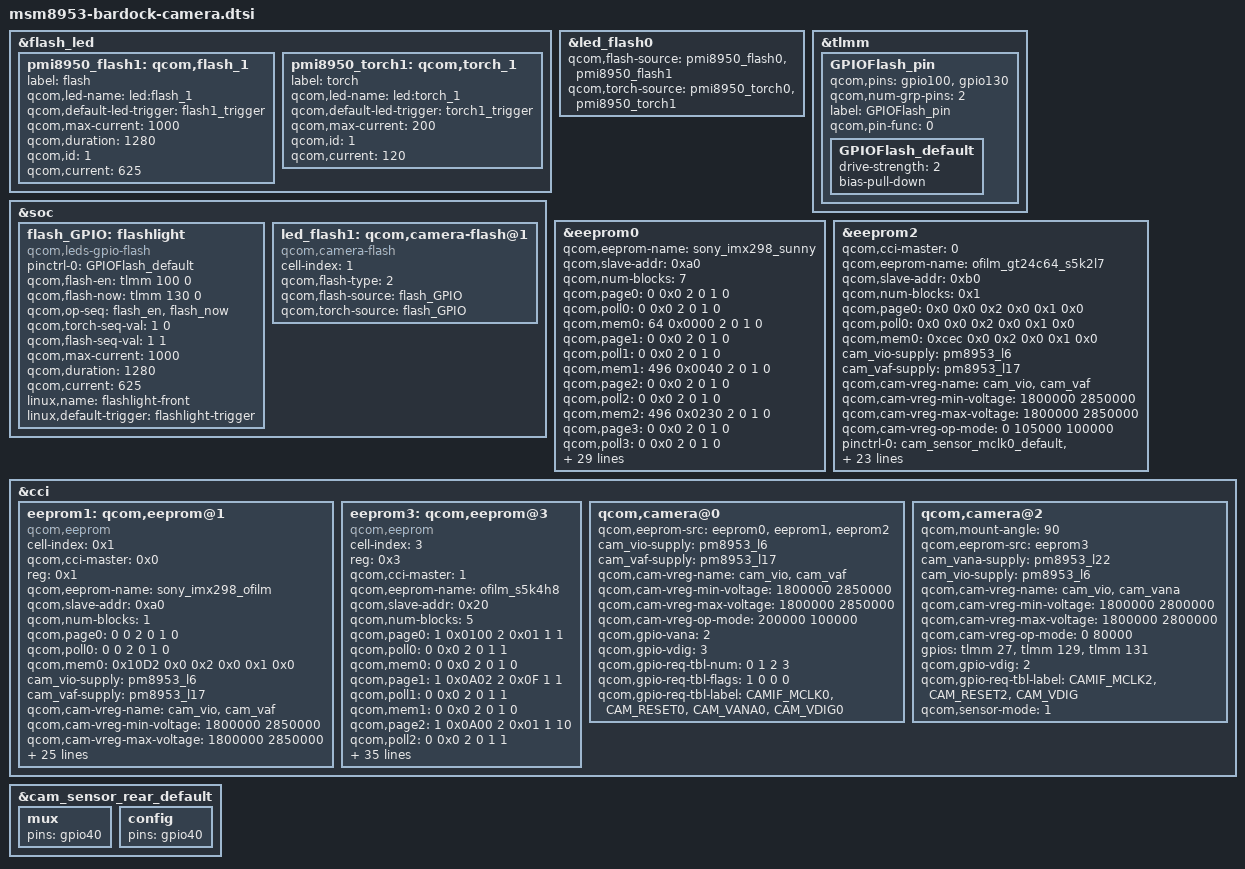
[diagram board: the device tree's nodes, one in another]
/*
 * Copyright (c) 2018, The LineageOS Project. All rights reserved.
 *
 * This program is free software; you can redistribute it and/or modify
 * it under the terms of the GNU General Public License version 2 and
 * only version 2 as published by the Free Software Foundation.
 *
 * This program is distributed in the hope that it will be useful,
 * but WITHOUT ANY WARRANTY; without even the implied warranty of
 * MERCHANTABILITY or FITNESS FOR A PARTICULAR PURPOSE.  See the
 * GNU General Public License for more details.
 */

&flash_led {
	pmi8950_flash1: qcom,flash_1 {
		label = "flash";
		qcom,led-name = "led:flash_1";
		qcom,default-led-trigger = "flash1_trigger";
		qcom,max-current = <1000>;
		qcom,duration = <1280>;
		qcom,id = <1>;
		qcom,current = <625>;
	};

	pmi8950_torch1: qcom,torch_1 {
		label = "torch";
		qcom,led-name = "led:torch_1";
		qcom,default-led-trigger = "torch1_trigger";
		qcom,max-current = <200>;
		qcom,id = <1>;
		qcom,current = <120>;
	};
};

&led_flash0 {
	qcom,flash-source = <&pmi8950_flash0 &pmi8950_flash1>;
	qcom,torch-source = <&pmi8950_torch0 &pmi8950_torch1>;
};

&tlmm {
	GPIOFlash_pin {
		qcom,pins = "gpio100", "gpio130";
		qcom,num-grp-pins = <2>;
		label = "GPIOFlash_pin";
		qcom,pin-func = <0>;

		GPIOFlash_default: GPIOFlash_default {
		drive-strength = <2>;
		bias-pull-down;
		};
	};
};

&soc {
	flash_GPIO:flashlight {
		compatible = "qcom,leds-gpio-flash";
		//status = "okay";
		pinctrl-names = "flash_default";
		pinctrl-0 = <&GPIOFlash_default>;
		qcom,flash-en = <&tlmm 100 0>;
		qcom,flash-now = <&tlmm 130 0>;
		qcom,op-seq = "flash_en", "flash_now";
		qcom,torch-seq-val = <1 0>;
		qcom,flash-seq-val = <1 1>;
                qcom,max-current = <1000>;
                qcom,duration = <1280>;
                qcom,current = <625>;
		linux,name = "flashlight-front";
		linux,default-trigger = "flashlight-trigger";
	};
	led_flash1: qcom,camera-flash@1{
		cell-index = <1>;
		compatible = "qcom,camera-flash";
		qcom,flash-type = <2>;
		qcom,flash-source = <&flash_GPIO>;
		qcom,torch-source = <&flash_GPIO>;
	};
};

	&eeprom0 {
		qcom,eeprom-name = "sony_imx298_sunny";
		qcom,slave-addr = <0xa0>;
		qcom,num-blocks = <7>;
		qcom,page0 = <0 0x0 2 0 1 0>;
		qcom,poll0 = <0 0x0 2 0 1 0>;
		qcom,mem0 = <64 0x0000 2 0 1 0>;
		qcom,page1 = <0 0x0 2 0 1 0>;
		qcom,poll1 = <0 0x0 2 0 1 0>;
		qcom,mem1 = <496 0x0040 2 0 1 0>;
		qcom,page2 = <0 0x0 2 0 1 0>;
		qcom,poll2 = <0 0x0 2 0 1 0>;
		qcom,mem2 = <496 0x0230 2 0 1 0>;
		qcom,page3 = <0 0x0 2 0 1 0>;
		qcom,poll3 = <0 0x0 2 0 1 0>;
		qcom,mem3 = <496 0x0420 2 0 1 0>;
		qcom,page4 = <0 0x0 2 0 1 0>;
		qcom,poll4 = <0 0x0 2 0 1 0>;
		qcom,mem4 = <496 0x0610 2 0 1 0>;
		qcom,page5 = <0 0x0 2 0 1 0>;
		qcom,poll5 = <0 0x0 2 0 1 0>;
		qcom,mem5 = <256 0x0800 2 0 1 0>;
		qcom,page6 = <0 0x0 2 0 1 0>;
		qcom,poll6 = <0 0x0 2 0 1 0>;
		qcom,mem6 = <98 0x0900 2 0 1 0>;

		qcom,cam-vreg-name = "cam_vio","cam_vaf";
		qcom,cam-vreg-min-voltage = <1800000 2850000>;
		qcom,cam-vreg-max-voltage = <1800000 2850000>;
		gpios = <&tlmm 26 0>,
			<&tlmm 40 0>,
			<&tlmm 39 0>,
			<&tlmm 131 0>;
		qcom,gpio-vana = <2>;
		qcom,gpio-vdig = <3>;
		qcom,gpio-req-tbl-num = <0 1 2 3 >;
		qcom,gpio-req-tbl-flags = <1 0 0 0>;
		qcom,gpio-req-tbl-label = "CAMIF_MCLK0",
			"CAM_RESET0",
			"CAM_VANA0",
			"CAM_VDIG0";
		qcom,cam-power-seq-type = "sensor_gpio",
					  "sensor_gpio", 
					  "sensor_gpio",
					  "sensor_vreg",
					  "sensor_vreg",
					  "sensor_clk",
					  "sensor_gpio";
		qcom,cam-power-seq-val =  "sensor_gpio_reset",
					  "sensor_gpio_vana",
					  "sensor_gpio_vdig",
					  "cam_vio",
					  "cam_vaf",
					  "sensor_cam_mclk",
					  "sensor_gpio_reset";
		qcom,cam-power-seq-cfg-val = <0 1 1 1 1 24000000 1>;
		qcom,cam-power-seq-delay = <1 0 0 0 5 1 28>;
		/delete-node/ cam_vdig-supply;
		/delete-node/ qcom,gpio-standby;
	};

	&eeprom2 {
		qcom,cci-master = <0>;
		qcom,eeprom-name = "ofilm_gt24c64_s5k2l7";
		qcom,slave-addr = <0xb0>;
		qcom,num-blocks = <0x1>;
		qcom,page0 = <0x0 0x0 0x2 0x0 0x1 0x0>;
		qcom,poll0 = <0x0 0x0 0x2 0x0 0x1 0x0>;
		qcom,mem0 = <0xcec 0x0 0x2 0x0 0x1 0x0>;

		cam_vio-supply = <&pm8953_l6>;
		cam_vaf-supply = <&pm8953_l17>;
		qcom,cam-vreg-name = "cam_vio", "cam_vaf";
		qcom,cam-vreg-min-voltage = <1800000 2850000>;
		qcom,cam-vreg-max-voltage = <1800000 2850000>;
		qcom,cam-vreg-op-mode = <0 105000 100000>;
		pinctrl-names = "cam_default", "cam_suspend";
		pinctrl-0 = <&cam_sensor_mclk0_default &cam_sensor_rear_default>;
		pinctrl-1 = <&cam_sensor_mclk0_sleep &cam_sensor_rear_sleep>;

		gpios = <&tlmm 26 0>,
			<&tlmm 40 0>,
			<&tlmm 39 0>,
			<&tlmm 131 0>;
		qcom,gpio-reset = <1>;
		qcom,gpio-vana = <2>;
		qcom,gpio-vdig = <3>;
		qcom,gpio-req-tbl-num = <0 1 2 3 >;
		qcom,gpio-req-tbl-flags = <1 0 0 0>;
		qcom,gpio-req-tbl-label = "CAMIF_MCLK0",
			"CAM_RESET0",
			"CAM_VANA0",
			"CAM_VDIG0";
		qcom,cam-power-seq-type = "sensor_gpio",
					  "sensor_gpio", 
					  "sensor_gpio",
					  "sensor_vreg",
					  "sensor_vreg",
					  "sensor_clk",
					  "sensor_gpio";
		qcom,cam-power-seq-val =  "sensor_gpio_reset",
					  "sensor_gpio_vana",
					  "sensor_gpio_vdig",
					  "cam_vio",
					  "cam_vaf",
					  "sensor_cam_mclk",
					  "sensor_gpio_reset";
		qcom,cam-power-seq-cfg-val = <0 1 1 1 1 24000000 1>;
		qcom,cam-power-seq-delay = <1 1 1 0 5 1 18>;

		status = "ok";

		clocks = <&clock_gcc clk_mclk0_clk_src>,
			 <&clock_gcc clk_gcc_camss_mclk0_clk>;
		clock-names = "cam_src_clk", "cam_clk";
		qcom,clock-rates = <19200000 0>;
		/delete-node/ cam_vdig-supply;
		/delete-node/ qcom,gpio-standby;
	};

&cci {
	eeprom1: qcom,eeprom@1 {
		compatible = "qcom,eeprom";
		cell-index = <0x1>;
		qcom,cci-master = <0x0>;
		reg = <0x1>;
		qcom,eeprom-name = "sony_imx298_ofilm";
		qcom,slave-addr = <0xa0>;
		qcom,num-blocks = <1>;
		qcom,page0 = <0 0 2 0 1 0>;
		qcom,poll0 = <0 0 2 0 1 0>;
		qcom,mem0 = <0x10D2 0x0 0x2 0x0 0x1 0x0>;
		cam_vio-supply = <&pm8953_l6>;
		cam_vaf-supply = <&pm8953_l17>;
		qcom,cam-vreg-name = "cam_vio", "cam_vaf";
		qcom,cam-vreg-min-voltage = <1800000 2850000>;
		qcom,cam-vreg-max-voltage = <1800000 2850000>;
		qcom,cam-vreg-op-mode = <0 105000 100000>;
		pinctrl-names = "cam_default", "cam_suspend";
		pinctrl-0 = <&cam_sensor_mclk0_default &cam_sensor_rear_default>;
		pinctrl-1 = <&cam_sensor_mclk0_sleep &cam_sensor_rear_sleep>;

		gpios = <&tlmm 26 0>,
			<&tlmm 40 0>,
			<&tlmm 39 0>,
			<&tlmm 131 0>;
		qcom,gpio-reset = <1>;
		qcom,gpio-vana = <2>;
		qcom,gpio-vdig = <3>;
		qcom,gpio-req-tbl-num = <0 1 2 3>;
		qcom,gpio-req-tbl-flags = <1 0 0 0>;
		qcom,gpio-req-tbl-label = "CAMIF_MCLK0",
			"CAM_RESET0",
			"CAM_VANA0",
			"CAM_VDIG0";
		qcom,cam-power-seq-type = "sensor_gpio",
					  "sensor_gpio",
					  "sensor_gpio",
					  "sensor_vreg",
					  "sensor_vreg",
					  "sensor_clk",
					  "sensor_gpio";
		qcom,cam-power-seq-val = "sensor_gpio_reset",
					 "sensor_gpio_vana",
					 "sensor_gpio_vdig",
					 "cam_vio",
					 "cam_vaf",
					 "sensor_cam_mclk",
					 "sensor_gpio_reset";
		qcom,cam-power-seq-cfg-val = <0 1 1 1 1 24000000 1>;
		qcom,cam-power-seq-delay = <1 0 0 0 5 1 28>;

		status = "ok";

		clocks = <&clock_gcc clk_mclk0_clk_src>,
			 <&clock_gcc clk_gcc_camss_mclk0_clk>;
		clock-names = "cam_src_clk", "cam_clk";
		qcom,clock-rates = <19200000 0>;
	};

	eeprom3: qcom,eeprom@3 {
		cell-index = <3>;
		reg = <0x3>;
		compatible = "qcom,eeprom";
		qcom,cci-master = <1>;
		qcom,eeprom-name = "ofilm_s5k4h8";
		qcom,slave-addr = <0x20>;
		qcom,num-blocks = <5>; 
	
	        //qcom,saddr0 = <0x20>;
		qcom,page0 = <1 0x0100 2 0x01 1 1>;
		qcom,poll0 = <0 0x0 2 0 1 1>;
		qcom,mem0 = <0 0x0 2 0 1 0>;
		
		//BANK 
		//qcom,saddr1 = <0x20>;
		qcom,page1 = <1 0x0A02 2 0x0F 1 1>;
		qcom,poll1 = <0 0x0 2 0 1 1>;
		qcom,mem1 = <0 0x0 2 0 1 0>;

		//qcom,saddr2 = <0x20>;
		qcom,page2 = <1 0x0A00 2 0x01 1 10>;
		qcom,poll2 = <0 0x0 2 0 1 1>;
		qcom,mem2 = <0 0x0 2 0 1 0>;

		//qcom,saddr3 = <0x20>;
		qcom,page3 = <0 0x0A02 2 0x0F 1 5>;
		qcom,poll3 = <0 0x0 2 0 1 1>;
		qcom,mem3 = <64 0x0A04 2 0 1 0>;

		//Disable NVM controller
		//qcom,saddr4 = <0x20>;
		qcom,page4 = <1 0x0A00 2 0x00 1 1>;
		qcom,poll4 = <0 0x0 2 0 1 1>;
		qcom,mem4 = <0 0x0 2 0 1 0>;


		/*cam_vdig-supply = <&pm8953_l23>;*/
		cam_vana-supply = <&pm8953_l22>;
		cam_vio-supply = <&pm8953_l6>;
		/*cam_vaf-supply = <&pm8953_l17>;*/
		/*qcom,cam-vreg-name = "cam_vdig", "cam_vio", "cam_vana",
							"cam_vaf";*/
		qcom,cam-vreg-name = "cam_vio", "cam_vana";
		qcom,cam-vreg-min-voltage = <1800000 2800000>;
		qcom,cam-vreg-max-voltage = <1800000 2800000>;
		qcom,cam-vreg-op-mode = <105000 0 80000>;
		pinctrl-names = "cam_default", "cam_suspend";
		pinctrl-0 = <&cam_sensor_mclk1_default
				&cam_sensor_front_default>;
		pinctrl-1 = <&cam_sensor_mclk1_sleep
				&cam_sensor_front_sleep>;
		gpios = <&tlmm 27 0>,
			<&tlmm 129 0>,
			/*<&tlmm 132 0>;*/
			<&tlmm 131 0>;
		qcom,gpio-reset = <1>;
		/*qcom,gpio-standby = <2>;*/
		qcom,gpio-vdig = <2>;
		qcom,gpio-req-tbl-num = <0 1 2>;
		qcom,gpio-req-tbl-flags = <1 0 0>;
		qcom,gpio-req-tbl-label = "CAMIF_MCLK2",
			"CAM_RESET2",
			"CAM_VDIG";
	
		status = "ok";
		qcom,cam-power-seq-type = "sensor_gpio",
			"sensor_vreg", "sensor_vreg",
			"sensor_clk", "sensor_gpio";
		qcom,cam-power-seq-val = "sensor_gpio_vdig",
			"cam_vana", "cam_vio",
			"sensor_cam_mclk",
			"sensor_gpio_reset";
		qcom,cam-power-seq-cfg-val = <1 1 1 24000000 1>;
		qcom,cam-power-seq-delay = <0 0 1 10 1>;
		clocks = <&clock_gcc clk_mclk1_clk_src>,
				<&clock_gcc clk_gcc_camss_mclk1_clk>;
		clock-names = "cam_src_clk", "cam_clk";
		qcom,clock-rates = <19200000 0>;

	};

	qcom,camera@0 {
		qcom,eeprom-src = <&eeprom0 &eeprom1 &eeprom2>;
		cam_vio-supply = <&pm8953_l6>;
		cam_vaf-supply = <&pm8953_l17>;
		qcom,cam-vreg-name = "cam_vio", "cam_vaf";
		qcom,cam-vreg-min-voltage = <1800000 2850000>;
		qcom,cam-vreg-max-voltage = <1800000 2850000>;
		qcom,cam-vreg-op-mode = <200000 100000>;
		qcom,gpio-vana = <2>;
		qcom,gpio-vdig = <3>;
		qcom,gpio-req-tbl-num = <0 1 2 3 >;
		qcom,gpio-req-tbl-flags = <1 0 0 0>;
		qcom,gpio-req-tbl-label = "CAMIF_MCLK0",
			"CAM_RESET0",
			"CAM_VANA0",
			"CAM_VDIG0";
		/delete-property/ cam_vdig-supply;
		/delete-property/ qcom,gpio-standby;
	};
	qcom,camera@2 {
		qcom,mount-angle = <90>;
		qcom,eeprom-src = <&eeprom3>;
		cam_vana-supply = <&pm8953_l22>;
		cam_vio-supply = <&pm8953_l6>;
		qcom,cam-vreg-name = "cam_vio", "cam_vana";
		qcom,cam-vreg-min-voltage = <1800000 2800000>;
		qcom,cam-vreg-max-voltage = <1800000 2800000>;
		qcom,cam-vreg-op-mode = <0 80000>;
		gpios = <&tlmm 27 0>,
			<&tlmm 129 0>,
			<&tlmm 131 0>;
		qcom,gpio-vdig = <2>;
		qcom,gpio-req-tbl-label = "CAMIF_MCLK2",
			"CAM_RESET2",
			"CAM_VDIG";
		qcom,sensor-mode = <1>;
		/delete-property/ cam_vdig-supply;
		/delete-property/ qcom,gpio-standby;
	};
	/delete-node/ qcom,camera@1;
};

&cam_sensor_rear_default {
	mux {
		pins = "gpio40";
	};
	config {
		pins = "gpio40";
	};
};

/*
&cam_sensor_rear_sleep {
	mux {
		pins = "gpio40";
	};
	config {
		pins = "gpio40";
	};
};
*/
